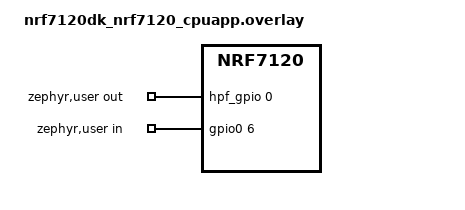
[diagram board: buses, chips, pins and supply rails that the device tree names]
/*
 * Copyright (c) 2026 Nordic Semiconductor ASA
 *
 * SPDX-License-Identifier: LicenseRef-Nordic-5-Clause
 */

/* Test requires GPIO loopback between P2.00 and P0.06. */

/ {
	/* Test requirements:
	 * out-gpios[0] wire connected with in-gpios[0],
	 * out-gpios[1] wire connected with in-gpios[1],
	 * etc.
	 * Output-input GPIO pair must have identical active level flag.
	 * All outputs must be on the same device.
	 */
	zephyr,user {
		out-gpios = <&hpf_gpio 0 GPIO_ACTIVE_HIGH>;
		in-gpios = <&gpio0 6 GPIO_ACTIVE_HIGH>;
	};
};

&gpiote20 {
	status = "okay";
};

&gpio0 {
	status = "okay";
};
